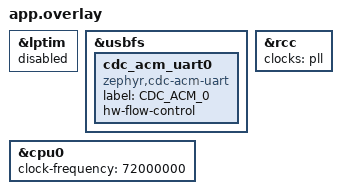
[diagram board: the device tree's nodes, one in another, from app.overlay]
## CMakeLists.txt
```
cmake_minimum_required(VERSION 3.20.0)
find_package(Zephyr REQUIRED HINTS $ENV{ZEPHYR_BASE})
project(wch_usbfs_cdc_test)

target_sources(app PRIVATE src/main.c)
zephyr_compile_options(-Wno-unused-variable)
```

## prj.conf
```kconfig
CONFIG_STDOUT_CONSOLE=y
CONFIG_SDI_CONSOLE=y
CONFIG_GPIO=y
CONFIG_LOG=y
CONFIG_CLOCK_CONTROL=y

# New USB Device Stack
CONFIG_USB_DEVICE_STACK_NEXT=y
CONFIG_USBD_CDC_ACM_CLASS=y

# Serial over CDC ACM helper
CONFIG_CDC_ACM_SERIAL_INITIALIZE_AT_BOOT=y
CONFIG_CDC_ACM_SERIAL_ENABLE_AT_BOOT=y

# Params
CONFIG_CDC_ACM_SERIAL_VID=0x1a86
CONFIG_CDC_ACM_SERIAL_PID=0x7523
CONFIG_CDC_ACM_SERIAL_MANUFACTURER_STRING="Zephyr"
CONFIG_CDC_ACM_SERIAL_PRODUCT_STRING="UDC Test"

# Debug
CONFIG_UDC_DRIVER_LOG_LEVEL_DBG=y
CONFIG_COMPILER_WARNINGS_AS_ERRORS=n
CONFIG_USB_DEVICE_DRIVER=n
CONFIG_LTO=y
CONFIG_ISR_TABLES_LOCAL_DECLARATION=y
```

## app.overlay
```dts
&lptim {
	status = "disabled";
};

&usbfs {
	status = "okay";
	cdc_acm_uart0: cdc_acm_uart0 {
		compatible = "zephyr,cdc-acm-uart";
		label = "CDC_ACM_0";
		hw-flow-control;
	};
};

&rcc {
    clocks = <&pll>;
};

&cpu0 {
    clock-frequency = <72000000>;
};
```

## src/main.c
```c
#include <zephyr/kernel.h>
#include <zephyr/sys/printk.h>

int main(void)
{
	k_busy_wait(3000000);
	printk("WCH USBFS CDC ACM Test (Next Stack)\n");
	printk("USB Should be enabled by Kconfig...\n");

	while (1) {
		k_sleep(K_SECONDS(1));
		printk("Alive...\n");
	}

	return 0;
}
```
